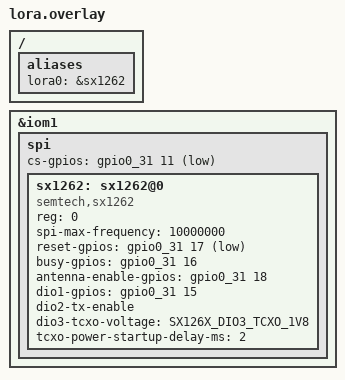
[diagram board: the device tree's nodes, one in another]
#include <zephyr/dt-bindings/lora/sx126x.h>
#include <zephyr/dt-bindings/input/input-event-codes.h>

/ {
   aliases {
       lora0 = &sx1262;
   };
};

&iom1 {
    spi {
        cs-gpios = <&gpio0_31 11 GPIO_ACTIVE_LOW>;
        sx1262: sx1262@0 {
            compatible = "semtech,sx1262";
            reg = <0>;
            spi-max-frequency = <10000000>;
            reset-gpios = <&gpio0_31 17 GPIO_ACTIVE_LOW>;
            busy-gpios = <&gpio0_31 16 GPIO_ACTIVE_HIGH>;
            antenna-enable-gpios = <&gpio0_31 18 GPIO_ACTIVE_HIGH>;
            dio1-gpios = <&gpio0_31 15 GPIO_ACTIVE_HIGH>;
            dio2-tx-enable;
            dio3-tcxo-voltage = <SX126X_DIO3_TCXO_1V8>;
            tcxo-power-startup-delay-ms = <2>;
            status = "okay";
        };
    };
};
